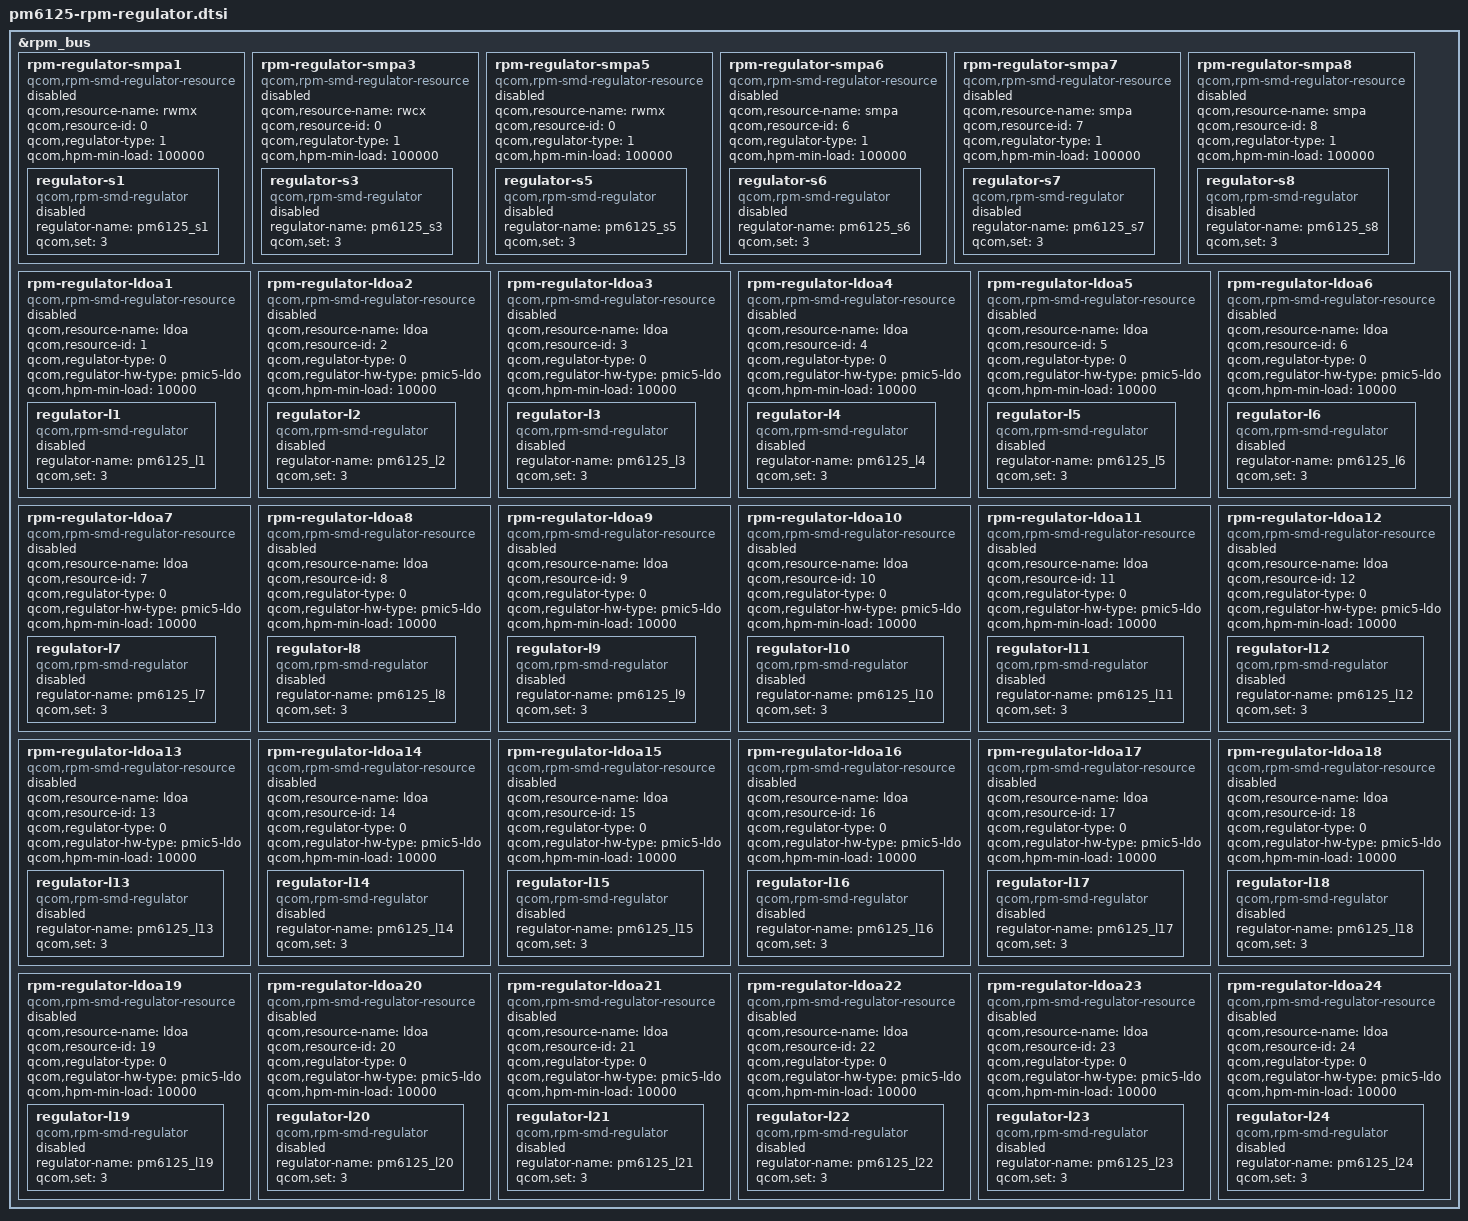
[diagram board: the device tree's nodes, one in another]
&rpm_bus {
	/* VDD_APC supply */
	rpm-regulator-smpa1 {
		compatible = "qcom,rpm-smd-regulator-resource";
		qcom,resource-name = "rwmx";
		qcom,resource-id = <0>;
		qcom,regulator-type = <1>;
		qcom,hpm-min-load = <100000>;
		status = "disabled";

		regulator-s1 {
			compatible = "qcom,rpm-smd-regulator";
			regulator-name = "pm6125_s1";
			qcom,set = <3>;
			status = "disabled";
		};
	};

	/* VDD_CX */
	rpm-regulator-smpa3 {
		compatible = "qcom,rpm-smd-regulator-resource";
		qcom,resource-name = "rwcx";
		qcom,resource-id = <0>;
		qcom,regulator-type = <1>;
		qcom,hpm-min-load = <100000>;
		status = "disabled";

		regulator-s3 {
			compatible = "qcom,rpm-smd-regulator";
			regulator-name = "pm6125_s3";
			qcom,set = <3>;
			status = "disabled";
		};
	};

	/* VDD_MX */
	rpm-regulator-smpa5 {
		compatible = "qcom,rpm-smd-regulator-resource";
		qcom,resource-name = "rwmx";
		qcom,resource-id = <0>;
		qcom,regulator-type = <1>;
		qcom,hpm-min-load = <100000>;
		status = "disabled";

		regulator-s5 {
			compatible = "qcom,rpm-smd-regulator";
			regulator-name = "pm6125_s5";
			qcom,set = <3>;
			status = "disabled";
		};
	};

	rpm-regulator-smpa6 {
		compatible = "qcom,rpm-smd-regulator-resource";
		qcom,resource-name = "smpa";
		qcom,resource-id = <6>;
		qcom,regulator-type = <1>;
		qcom,hpm-min-load = <100000>;
		status = "disabled";

		regulator-s6 {
			compatible = "qcom,rpm-smd-regulator";
			regulator-name = "pm6125_s6";
			qcom,set = <3>;
			status = "disabled";
		};
	};

	rpm-regulator-smpa7 {
		compatible = "qcom,rpm-smd-regulator-resource";
		qcom,resource-name = "smpa";
		qcom,resource-id = <7>;
		qcom,regulator-type = <1>;
		qcom,hpm-min-load = <100000>;
		status = "disabled";

		regulator-s7 {
			compatible = "qcom,rpm-smd-regulator";
			regulator-name = "pm6125_s7";
			qcom,set = <3>;
			status = "disabled";
		};
	};

	rpm-regulator-smpa8 {
		compatible = "qcom,rpm-smd-regulator-resource";
		qcom,resource-name = "smpa";
		qcom,resource-id = <8>;
		qcom,regulator-type = <1>;
		qcom,hpm-min-load = <100000>;
		status = "disabled";

		regulator-s8 {
			compatible = "qcom,rpm-smd-regulator";
			regulator-name = "pm6125_s8";
			qcom,set = <3>;
			status = "disabled";
		};
	};

	rpm-regulator-ldoa1 {
		compatible = "qcom,rpm-smd-regulator-resource";
		qcom,resource-name = "ldoa";
		qcom,resource-id = <1>;
		qcom,regulator-type = <0>;
		qcom,regulator-hw-type = "pmic5-ldo";
		qcom,hpm-min-load = <10000>;
		status = "disabled";

		regulator-l1 {
			compatible = "qcom,rpm-smd-regulator";
			regulator-name = "pm6125_l1";
			qcom,set = <3>;
			status = "disabled";
		};
	};

	rpm-regulator-ldoa2 {
		compatible = "qcom,rpm-smd-regulator-resource";
		qcom,resource-name = "ldoa";
		qcom,resource-id = <2>;
		qcom,regulator-type = <0>;
		qcom,regulator-hw-type = "pmic5-ldo";
		qcom,hpm-min-load = <10000>;
		status = "disabled";

		regulator-l2 {
			compatible = "qcom,rpm-smd-regulator";
			regulator-name = "pm6125_l2";
			qcom,set = <3>;
			status = "disabled";
		};
	};

	rpm-regulator-ldoa3 {
		compatible = "qcom,rpm-smd-regulator-resource";
		qcom,resource-name = "ldoa";
		qcom,resource-id = <3>;
		qcom,regulator-type = <0>;
		qcom,regulator-hw-type = "pmic5-ldo";
		qcom,hpm-min-load = <10000>;
		status = "disabled";

		regulator-l3 {
			compatible = "qcom,rpm-smd-regulator";
			regulator-name = "pm6125_l3";
			qcom,set = <3>;
			status = "disabled";
		};
	};

	rpm-regulator-ldoa4 {
		compatible = "qcom,rpm-smd-regulator-resource";
		qcom,resource-name = "ldoa";
		qcom,resource-id = <4>;
		qcom,regulator-type = <0>;
		qcom,regulator-hw-type = "pmic5-ldo";
		qcom,hpm-min-load = <10000>;
		status = "disabled";

		regulator-l4 {
			compatible = "qcom,rpm-smd-regulator";
			regulator-name = "pm6125_l4";
			qcom,set = <3>;
			status = "disabled";
		};
	};

	rpm-regulator-ldoa5 {
		compatible = "qcom,rpm-smd-regulator-resource";
		qcom,resource-name = "ldoa";
		qcom,resource-id = <5>;
		qcom,regulator-type = <0>;
		qcom,regulator-hw-type = "pmic5-ldo";
		qcom,hpm-min-load = <10000>;
		status = "disabled";

		regulator-l5 {
			compatible = "qcom,rpm-smd-regulator";
			regulator-name = "pm6125_l5";
			qcom,set = <3>;
			status = "disabled";
		};
	};

	rpm-regulator-ldoa6 {
		compatible = "qcom,rpm-smd-regulator-resource";
		qcom,resource-name = "ldoa";
		qcom,resource-id = <6>;
		qcom,regulator-type = <0>;
		qcom,regulator-hw-type = "pmic5-ldo";
		qcom,hpm-min-load = <10000>;
		status = "disabled";

		regulator-l6 {
			compatible = "qcom,rpm-smd-regulator";
			regulator-name = "pm6125_l6";
			qcom,set = <3>;
			status = "disabled";
		};
	};

	rpm-regulator-ldoa7 {
		compatible = "qcom,rpm-smd-regulator-resource";
		qcom,resource-name = "ldoa";
		qcom,resource-id = <7>;
		qcom,regulator-type = <0>;
		qcom,regulator-hw-type = "pmic5-ldo";
		qcom,hpm-min-load = <10000>;
		status = "disabled";

		regulator-l7 {
			compatible = "qcom,rpm-smd-regulator";
			regulator-name = "pm6125_l7";
			qcom,set = <3>;
			status = "disabled";
		};
	};

	/* VDD_WCSS_CX */
	rpm-regulator-ldoa8 {
		compatible = "qcom,rpm-smd-regulator-resource";
		qcom,resource-name = "ldoa";
		qcom,resource-id = <8>;
		qcom,regulator-type = <0>;
		qcom,regulator-hw-type = "pmic5-ldo";
		qcom,hpm-min-load = <10000>;
		status = "disabled";

		regulator-l8 {
			compatible = "qcom,rpm-smd-regulator";
			regulator-name = "pm6125_l8";
			qcom,set = <3>;
			status = "disabled";
		};
	};

	rpm-regulator-ldoa9 {
		compatible = "qcom,rpm-smd-regulator-resource";
		qcom,resource-name = "ldoa";
		qcom,resource-id = <9>;
		qcom,regulator-type = <0>;
		qcom,regulator-hw-type = "pmic5-ldo";
		qcom,hpm-min-load = <10000>;
		status = "disabled";

		regulator-l9 {
			compatible = "qcom,rpm-smd-regulator";
			regulator-name = "pm6125_l9";
			qcom,set = <3>;
			status = "disabled";
		};
	};

	rpm-regulator-ldoa10 {
		compatible = "qcom,rpm-smd-regulator-resource";
		qcom,resource-name = "ldoa";
		qcom,resource-id = <10>;
		qcom,regulator-type = <0>;
		qcom,regulator-hw-type = "pmic5-ldo";
		qcom,hpm-min-load = <10000>;
		status = "disabled";

		regulator-l10 {
			compatible = "qcom,rpm-smd-regulator";
			regulator-name = "pm6125_l10";
			qcom,set = <3>;
			status = "disabled";
		};
	};

	rpm-regulator-ldoa11 {
		compatible = "qcom,rpm-smd-regulator-resource";
		qcom,resource-name = "ldoa";
		qcom,resource-id = <11>;
		qcom,regulator-type = <0>;
		qcom,regulator-hw-type = "pmic5-ldo";
		qcom,hpm-min-load = <10000>;
		status = "disabled";

		regulator-l11 {
			compatible = "qcom,rpm-smd-regulator";
			regulator-name = "pm6125_l11";
			qcom,set = <3>;
			status = "disabled";
		};
	};

	rpm-regulator-ldoa12 {
		compatible = "qcom,rpm-smd-regulator-resource";
		qcom,resource-name = "ldoa";
		qcom,resource-id = <12>;
		qcom,regulator-type = <0>;
		qcom,regulator-hw-type = "pmic5-ldo";
		qcom,hpm-min-load = <10000>;
		status = "disabled";

		regulator-l12 {
			compatible = "qcom,rpm-smd-regulator";
			regulator-name = "pm6125_l12";
			qcom,set = <3>;
			status = "disabled";
		};
	};

	rpm-regulator-ldoa13 {
		compatible = "qcom,rpm-smd-regulator-resource";
		qcom,resource-name = "ldoa";
		qcom,resource-id = <13>;
		qcom,regulator-type = <0>;
		qcom,regulator-hw-type = "pmic5-ldo";
		qcom,hpm-min-load = <10000>;
		status = "disabled";

		regulator-l13 {
			compatible = "qcom,rpm-smd-regulator";
			regulator-name = "pm6125_l13";
			qcom,set = <3>;
			status = "disabled";
		};
	};

	rpm-regulator-ldoa14 {
		compatible = "qcom,rpm-smd-regulator-resource";
		qcom,resource-name = "ldoa";
		qcom,resource-id = <14>;
		qcom,regulator-type = <0>;
		qcom,regulator-hw-type = "pmic5-ldo";
		qcom,hpm-min-load = <10000>;
		status = "disabled";

		regulator-l14 {
			compatible = "qcom,rpm-smd-regulator";
			regulator-name = "pm6125_l14";
			qcom,set = <3>;
			status = "disabled";
		};
	};

	rpm-regulator-ldoa15 {
		compatible = "qcom,rpm-smd-regulator-resource";
		qcom,resource-name = "ldoa";
		qcom,resource-id = <15>;
		qcom,regulator-type = <0>;
		qcom,regulator-hw-type = "pmic5-ldo";
		qcom,hpm-min-load = <10000>;
		status = "disabled";

		regulator-l15 {
			compatible = "qcom,rpm-smd-regulator";
			regulator-name = "pm6125_l15";
			qcom,set = <3>;
			status = "disabled";
		};
	};

	rpm-regulator-ldoa16 {
		compatible = "qcom,rpm-smd-regulator-resource";
		qcom,resource-name = "ldoa";
		qcom,resource-id = <16>;
		qcom,regulator-type = <0>;
		qcom,regulator-hw-type = "pmic5-ldo";
		qcom,hpm-min-load = <10000>;
		status = "disabled";

		regulator-l16 {
			compatible = "qcom,rpm-smd-regulator";
			regulator-name = "pm6125_l16";
			qcom,set = <3>;
			status = "disabled";
		};
	};

	rpm-regulator-ldoa17 {
		compatible = "qcom,rpm-smd-regulator-resource";
		qcom,resource-name = "ldoa";
		qcom,resource-id = <17>;
		qcom,regulator-type = <0>;
		qcom,regulator-hw-type = "pmic5-ldo";
		qcom,hpm-min-load = <10000>;
		status = "disabled";

		regulator-l17 {
			compatible = "qcom,rpm-smd-regulator";
			regulator-name = "pm6125_l17";
			qcom,set = <3>;
			status = "disabled";
		};
	};

	rpm-regulator-ldoa18 {
		compatible = "qcom,rpm-smd-regulator-resource";
		qcom,resource-name = "ldoa";
		qcom,resource-id = <18>;
		qcom,regulator-type = <0>;
		qcom,regulator-hw-type = "pmic5-ldo";
		qcom,hpm-min-load = <10000>;
		status = "disabled";

		regulator-l18 {
			compatible = "qcom,rpm-smd-regulator";
			regulator-name = "pm6125_l18";
			qcom,set = <3>;
			status = "disabled";
		};
	};

	rpm-regulator-ldoa19 {
		compatible = "qcom,rpm-smd-regulator-resource";
		qcom,resource-name = "ldoa";
		qcom,resource-id = <19>;
		qcom,regulator-type = <0>;
		qcom,regulator-hw-type = "pmic5-ldo";
		qcom,hpm-min-load = <10000>;
		status = "disabled";

		regulator-l19 {
			compatible = "qcom,rpm-smd-regulator";
			regulator-name = "pm6125_l19";
			qcom,set = <3>;
			status = "disabled";
		};
	};

	rpm-regulator-ldoa20 {
		compatible = "qcom,rpm-smd-regulator-resource";
		qcom,resource-name = "ldoa";
		qcom,resource-id = <20>;
		qcom,regulator-type = <0>;
		qcom,regulator-hw-type = "pmic5-ldo";
		qcom,hpm-min-load = <10000>;
		status = "disabled";

		regulator-l20 {
			compatible = "qcom,rpm-smd-regulator";
			regulator-name = "pm6125_l20";
			qcom,set = <3>;
			status = "disabled";
		};
	};

	rpm-regulator-ldoa21 {
		compatible = "qcom,rpm-smd-regulator-resource";
		qcom,resource-name = "ldoa";
		qcom,resource-id = <21>;
		qcom,regulator-type = <0>;
		qcom,regulator-hw-type = "pmic5-ldo";
		qcom,hpm-min-load = <10000>;
		status = "disabled";

		regulator-l21 {
			compatible = "qcom,rpm-smd-regulator";
			regulator-name = "pm6125_l21";
			qcom,set = <3>;
			status = "disabled";
		};
	};

	rpm-regulator-ldoa22 {
		compatible = "qcom,rpm-smd-regulator-resource";
		qcom,resource-name = "ldoa";
		qcom,resource-id = <22>;
		qcom,regulator-type = <0>;
		qcom,regulator-hw-type = "pmic5-ldo";
		qcom,hpm-min-load = <10000>;
		status = "disabled";

		regulator-l22 {
			compatible = "qcom,rpm-smd-regulator";
			regulator-name = "pm6125_l22";
			qcom,set = <3>;
			status = "disabled";
		};
	};

	rpm-regulator-ldoa23 {
		compatible = "qcom,rpm-smd-regulator-resource";
		qcom,resource-name = "ldoa";
		qcom,resource-id = <23>;
		qcom,regulator-type = <0>;
		qcom,regulator-hw-type = "pmic5-ldo";
		qcom,hpm-min-load = <10000>;
		status = "disabled";

		regulator-l23 {
			compatible = "qcom,rpm-smd-regulator";
			regulator-name = "pm6125_l23";
			qcom,set = <3>;
			status = "disabled";
		};
	};

	rpm-regulator-ldoa24 {
		compatible = "qcom,rpm-smd-regulator-resource";
		qcom,resource-name = "ldoa";
		qcom,resource-id = <24>;
		qcom,regulator-type = <0>;
		qcom,regulator-hw-type = "pmic5-ldo";
		qcom,hpm-min-load = <10000>;
		status = "disabled";

		regulator-l24 {
			compatible = "qcom,rpm-smd-regulator";
			regulator-name = "pm6125_l24";
			qcom,set = <3>;
			status = "disabled";
		};
	};
};
